VERSION "1.0"

NS_ :

BS_:

BU_: BCM ECM TESTER

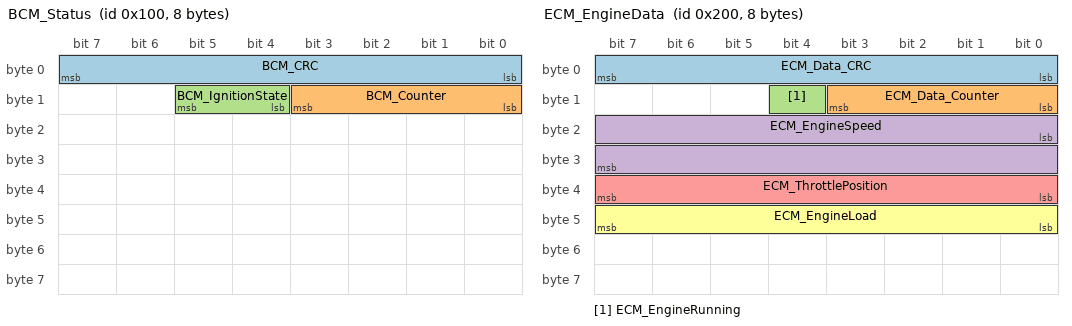
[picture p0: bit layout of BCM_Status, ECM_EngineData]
BO_ 256 BCM_Status: 8 BCM
 SG_ BCM_CRC : 0|8@1+ (1,0) [0|255] "" ECM
 SG_ BCM_Counter : 8|4@1+ (1,0) [0|15] "" ECM
 SG_ BCM_IgnitionState : 12|2@1+ (1,0) [0|3] "" ECM

BO_ 512 ECM_EngineData: 8 ECM
 SG_ ECM_Data_CRC : 0|8@1+ (1,0) [0|255] "" BCM,TESTER
 SG_ ECM_Data_Counter : 8|4@1+ (1,0) [0|15] "" BCM,TESTER
 SG_ ECM_EngineRunning : 12|1@1+ (1,0) [0|1] "" BCM,TESTER
 SG_ ECM_EngineSpeed : 16|16@1+ (0.25,0) [0|16383.75] "rpm" BCM,TESTER
 SG_ ECM_ThrottlePosition : 32|8@1+ (0.4,0) [0|100] "%" BCM,TESTER
 SG_ ECM_EngineLoad : 40|8@1+ (0.4,0) [0|100] "%" BCM,TESTER

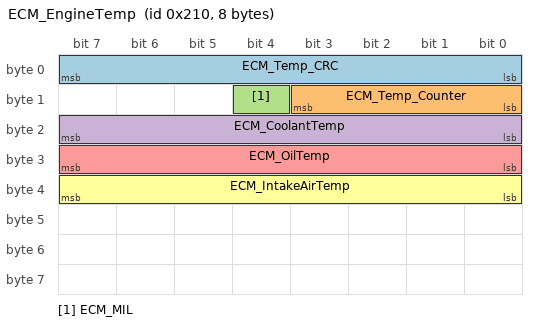
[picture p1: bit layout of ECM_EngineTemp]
BO_ 528 ECM_EngineTemp: 8 ECM
 SG_ ECM_Temp_CRC : 0|8@1+ (1,0) [0|255] "" BCM,TESTER
 SG_ ECM_Temp_Counter : 8|4@1+ (1,0) [0|15] "" BCM,TESTER
 SG_ ECM_MIL : 12|1@1+ (1,0) [0|1] "" BCM,TESTER
 SG_ ECM_CoolantTemp : 16|8@1+ (1,-40) [-40|215] "degC" BCM,TESTER
 SG_ ECM_OilTemp : 24|8@1+ (1,-40) [-40|215] "degC" BCM,TESTER
 SG_ ECM_IntakeAirTemp : 32|8@1+ (1,-40) [-40|215] "degC" BCM,TESTER

BO_ 2015 DIAG_Functional_Req: 8 TESTER

BO_ 2016 ECM_Diag_Req: 8 TESTER

BO_ 2024 ECM_Diag_Resp: 8 ECM

CM_ BU_ BCM "Rest-bus simulation: Body Control Module, provides ignition state.";
CM_ BU_ ECM "Engine Control Module - the simulated ECU under test.";
CM_ BU_ TESTER "Diagnostic tester (workshop tool).";
CM_ BO_ 256 "Ignition state from BCM, cyclic 100 ms. Timeout (>500 ms) sets DTC U0140 in ECM.";
CM_ BO_ 512 "Fast engine data, cyclic 20 ms.";
CM_ BO_ 528 "Engine temperatures and MIL, cyclic 100 ms.";
CM_ BO_ 2015 "UDS functional request (all ECUs), ISO-TP.";
CM_ BO_ 2016 "UDS physical request to ECM, ISO-TP.";
CM_ BO_ 2024 "UDS physical response from ECM, ISO-TP.";
CM_ SG_ 256 BCM_CRC "CRC8 SAE-J1850 over bytes 1..7.";
CM_ SG_ 256 BCM_Counter "Alive counter, increments 0..15 every frame.";
CM_ SG_ 512 ECM_Data_CRC "CRC8 SAE-J1850 over bytes 1..7.";
CM_ SG_ 512 ECM_Data_Counter "Alive counter, increments 0..15 every frame.";
CM_ SG_ 528 ECM_Temp_CRC "CRC8 SAE-J1850 over bytes 1..7.";
CM_ SG_ 528 ECM_Temp_Counter "Alive counter, increments 0..15 every frame.";
CM_ SG_ 528 ECM_MIL "Malfunction Indicator Lamp (check engine). 1 = confirmed emission DTC active.";
CM_ SG_ 528 ECM_CoolantTemp "Raw 0xFF = SNA (signal not available), sent when sensor is faulty (P0117/P0118).";

BA_DEF_ BO_ "GenMsgCycleTime" INT 0 10000;
BA_DEF_ BO_ "GenMsgSendType" STRING ;
BA_DEF_ "BusType" STRING ;
BA_DEF_DEF_ "GenMsgCycleTime" 0;
BA_DEF_DEF_ "GenMsgSendType" "Cyclic";
BA_DEF_DEF_ "BusType" "CAN";
BA_ "GenMsgCycleTime" BO_ 256 100;
BA_ "GenMsgCycleTime" BO_ 512 20;
BA_ "GenMsgCycleTime" BO_ 528 100;
BA_ "GenMsgSendType" BO_ 2015 "OnEvent";
BA_ "GenMsgSendType" BO_ 2016 "OnEvent";
BA_ "GenMsgSendType" BO_ 2024 "OnEvent";

VAL_ 256 BCM_IgnitionState 0 "OFF" 1 "ACC" 2 "ON" 3 "START" ;
VAL_ 512 ECM_EngineRunning 0 "STOPPED" 1 "RUNNING" ;
VAL_ 528 ECM_MIL 0 "OFF" 1 "ON" ;
VAL_ 528 ECM_CoolantTemp 255 "SNA" ;
VAL_ 528 ECM_OilTemp 255 "SNA" ;
VAL_ 528 ECM_IntakeAirTemp 255 "SNA" ;
